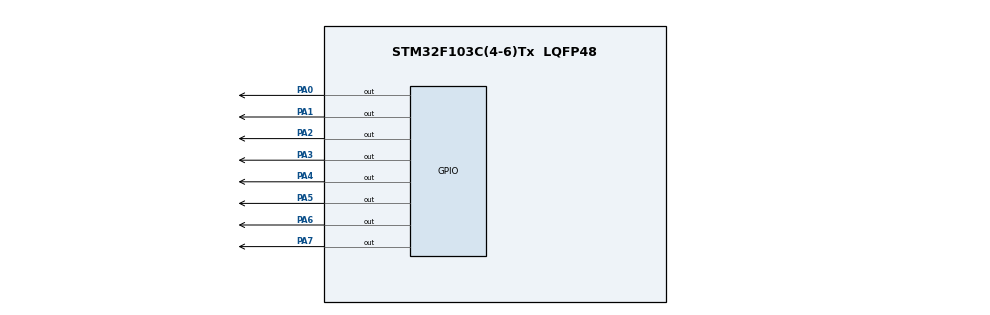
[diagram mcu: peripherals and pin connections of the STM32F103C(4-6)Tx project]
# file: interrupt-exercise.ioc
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Mcu.Family=STM32F1
Mcu.Name=STM32F103C(4-6)Tx
Mcu.Package=LQFP48
NVIC.PriorityGroup=NVIC_PRIORITYGROUP_4
NVIC.TIM3_IRQn=true\:0\:0\:false\:false\:true\:true\:true
PA0-WKUP.PinState=GPIO_PIN_SET
PA0-WKUP.Signal=GPIO_Output
PA1.PinState=GPIO_PIN_SET
PA1.Signal=GPIO_Output
PA2.PinState=GPIO_PIN_SET
PA2.Signal=GPIO_Output
PA3.PinState=GPIO_PIN_SET
PA3.Signal=GPIO_Output
PA4.PinState=GPIO_PIN_SET
PA4.Signal=GPIO_Output
PA5.PinState=GPIO_PIN_SET
PA5.Signal=GPIO_Output
PA6.PinState=GPIO_PIN_SET
PA6.Signal=GPIO_Output
PA7.PinState=GPIO_PIN_SET
PA7.Signal=GPIO_Output
PD0-OSC_IN.Mode=HSE-External-Oscillator
PD0-OSC_IN.Signal=RCC_OSC_IN
PD1-OSC_OUT.Mode=HSE-External-Oscillator
PD1-OSC_OUT.Signal=RCC_OSC_OUT
ProjectManager.HeapSize=0x200
ProjectManager.StackSize=0x400
ProjectManager.TargetToolchain=STM32CubeIDE
RCC.APB1Freq_Value=8000000
RCC.APB2Freq_Value=8000000
RCC.SYSCLKSource=RCC_SYSCLKSOURCE_HSE
TIM3.Period=1000
TIM3.Prescaler=8000 - 1
VP_SYS_VS_ND.Mode=No_Debug
VP_TIM3_VS_ClockSourceINT.Mode=Internal
board=custom

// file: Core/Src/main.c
/* USER CODE BEGIN Header */
/**
  ******************************************************************************
  * @file           : main.c
  * @brief          : Main program body
  ******************************************************************************
  * @attention
  *
  * <h2><center>&copy; Copyright (c) 2021 STMicroelectronics.
  * All rights reserved.</center></h2>
  *
  * This software component is licensed by ST under BSD 3-Clause license,
  * the "License"; You may not use this file except in compliance with the
  * License. You may obtain a copy of the License at:
  *                        opensource.org/licenses/BSD-3-Clause
  *
  ******************************************************************************
  */
/* USER CODE END Header */
#include "main.h"

/* USER CODE BEGIN Includes */
#include "sqr_wave_generator.h"
/* USER CODE END Includes */

//TIM_HandleTypeDef htim3;

void SystemClock_Config(void);
static void MX_GPIO_Init(void);
static void MX_TIM3_Init(void);

int main(void)
{

  /* MCU Configuration--------------------------------------------------------*/

  /* Reset of all peripherals, Initializes the Flash interface and the Systick. */
  HAL_Init();

  /* Configure the system clock */
  SystemClock_Config();

  /* Initialize all configured peripherals */
  MX_GPIO_Init();
  MX_TIM3_Init();
  /* USER CODE BEGIN 2 */
  sqrWaveGenerator_setup();
  /* USER CODE END 2 */

  /* Infinite loop */
  while (1)
  {
	  sqrWaveGeneratorDriver_drive();
  }
}

void SystemClock_Config(void)
{
  RCC_OscInitTypeDef RCC_OscInitStruct = {0};
  RCC_ClkInitTypeDef RCC_ClkInitStruct = {0};

  /** Initializes the RCC Oscillators according to the specified parameters
  * in the RCC_OscInitTypeDef structure.
  */
  RCC_OscInitStruct.OscillatorType = RCC_OSCILLATORTYPE_HSE;
  RCC_OscInitStruct.HSEState = RCC_HSE_ON;
  RCC_OscInitStruct.PLL.PLLState = RCC_PLL_NONE;
  if (HAL_RCC_OscConfig(&RCC_OscInitStruct) != HAL_OK)
  {
    Error_Handler();
  }
  /** Initializes the CPU, AHB and APB buses clocks
  */
  RCC_ClkInitStruct.ClockType = RCC_CLOCKTYPE_HCLK|RCC_CLOCKTYPE_SYSCLK
                              |RCC_CLOCKTYPE_PCLK1|RCC_CLOCKTYPE_PCLK2;
  RCC_ClkInitStruct.SYSCLKSource = RCC_SYSCLKSOURCE_HSE;
  RCC_ClkInitStruct.AHBCLKDivider = RCC_SYSCLK_DIV1;
  RCC_ClkInitStruct.APB1CLKDivider = RCC_HCLK_DIV1;
  RCC_ClkInitStruct.APB2CLKDivider = RCC_HCLK_DIV1;

  if (HAL_RCC_ClockConfig(&RCC_ClkInitStruct, FLASH_LATENCY_0) != HAL_OK)
  {
    Error_Handler();
  }
}

static void MX_TIM3_Init(void)
{

  TIM_ClockConfigTypeDef sClockSourceConfig = {0};
  TIM_MasterConfigTypeDef sMasterConfig = {0};

  htim3.Instance = TIM3;
  htim3.Init.Prescaler = 8 - 1;
  htim3.Init.CounterMode = TIM_COUNTERMODE_UP;
  htim3.Init.Period = 65536 - 1;
  htim3.Init.ClockDivision = TIM_CLOCKDIVISION_DIV1;
  htim3.Init.AutoReloadPreload = TIM_AUTORELOAD_PRELOAD_DISABLE;
  if (HAL_TIM_Base_Init(&htim3) != HAL_OK)
  {
    Error_Handler();
  }
  sClockSourceConfig.ClockSource = TIM_CLOCKSOURCE_INTERNAL;
  if (HAL_TIM_ConfigClockSource(&htim3, &sClockSourceConfig) != HAL_OK)
  {
    Error_Handler();
  }
  sMasterConfig.MasterOutputTrigger = TIM_TRGO_RESET;
  sMasterConfig.MasterSlaveMode = TIM_MASTERSLAVEMODE_DISABLE;
  if (HAL_TIMEx_MasterConfigSynchronization(&htim3, &sMasterConfig) != HAL_OK)
  {
    Error_Handler();
  }

}

static void MX_GPIO_Init(void)
{
  GPIO_InitTypeDef GPIO_InitStruct = {0};

  /* GPIO Ports Clock Enable */
  __HAL_RCC_GPIOD_CLK_ENABLE();
  __HAL_RCC_GPIOA_CLK_ENABLE();

  /*Configure GPIO pin Output Level */
  HAL_GPIO_WritePin(GPIOA, GPIO_PIN_5, GPIO_PIN_SET);

  /*Configure GPIO pin : PA5 */
  GPIO_InitStruct.Pin = GPIO_PIN_5;
  GPIO_InitStruct.Mode = GPIO_MODE_OUTPUT_PP;
  GPIO_InitStruct.Pull = GPIO_NOPULL;
  GPIO_InitStruct.Speed = GPIO_SPEED_FREQ_LOW;
  HAL_GPIO_Init(GPIOA, &GPIO_InitStruct);

}

void Error_Handler(void)
{
  __disable_irq();
  while (1)
  {
  }
}

/************************ (C) COPYRIGHT STMicroelectronics *****END OF FILE****/
